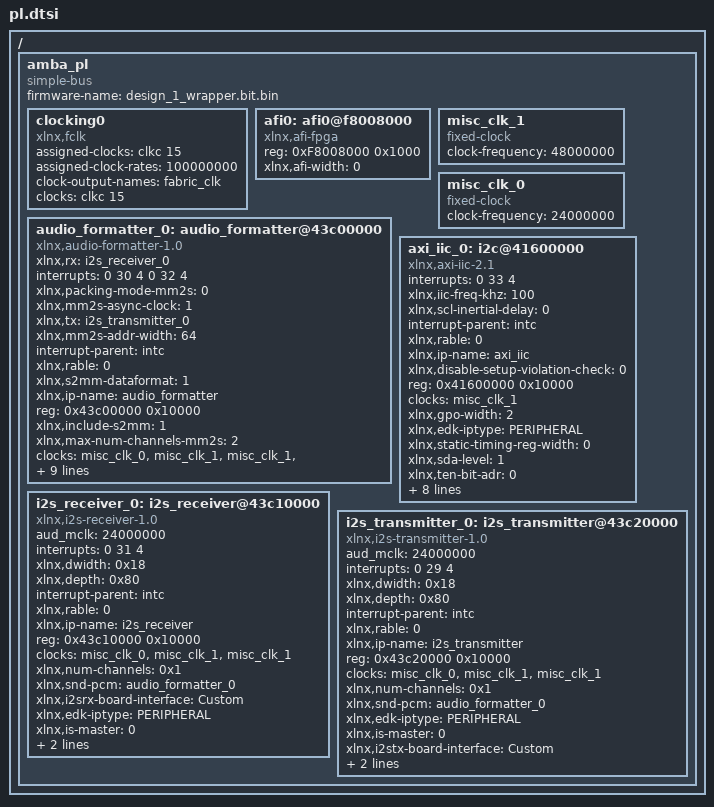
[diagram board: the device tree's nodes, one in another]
/ {
	amba_pl: amba_pl {
		ranges;
		compatible = "simple-bus";
		#address-cells = <1>;
		#size-cells = <1>;
		firmware-name = "design_1_wrapper.bit.bin";
		clocking0: clocking0 {
			compatible = "xlnx,fclk";
			assigned-clocks = <&clkc 15>;
			assigned-clock-rates = <100000000>;
			#clock-cells = <0>;
			clock-output-names = "fabric_clk";
			clocks = <&clkc 15>;
		};
		afi0: afi0@f8008000 {
			status = "okay";
			compatible = "xlnx,afi-fpga";
			#address-cells = <1>;
			reg = <0xF8008000 0x1000>;
			#size-cells = <0>;
			xlnx,afi-width = <0>;
		};
		misc_clk_1: misc_clk_1 {
			compatible = "fixed-clock";
			clock-frequency = <48000000>;
			#clock-cells = <0>;
		};
		misc_clk_0: misc_clk_0 {
			compatible = "fixed-clock";
			clock-frequency = <24000000>;
			#clock-cells = <0>;
		};
		audio_formatter_0: audio_formatter@43c00000 {
			xlnx,rx = <&i2s_receiver_0>;
			interrupts = < 0 30 4 0 32 4 >;
			compatible = "xlnx,audio-formatter-1.0" , "xlnx,audio-formatter-1.0";
			xlnx,packing-mode-mm2s = <0>;
			xlnx,mm2s-async-clock = <1>;
			xlnx,tx = <&i2s_transmitter_0>;
			xlnx,mm2s-addr-width = <64>;
			interrupt-parent = <&intc>;
			xlnx,rable = <0>;
			xlnx,s2mm-dataformat = <1>;
			xlnx,ip-name = "audio_formatter";
			reg = <0x43c00000 0x10000>;
			xlnx,include-s2mm = <1>;
			xlnx,max-num-channels-mm2s = <2>;
			clocks = <&misc_clk_0>, <&misc_clk_1>, <&misc_clk_1>, <&misc_clk_1>;
			xlnx,s2mm-async-clock = <1>;
			xlnx,packing-mode-s2mm = <0>;
			xlnx,edk-iptype = "PERIPHERAL";
			xlnx,s2mm-addr-width = <64>;
			status = "okay";
			clock-names = "aud_mclk" , "m_axis_mm2s_aclk" , "s_axi_lite_aclk" , "s_axis_s2mm_aclk";
			xlnx,mm2s-dataformat = <3>;
			interrupt-names = "irq_mm2s" , "irq_s2mm";
			xlnx,include-mm2s = <1>;
			xlnx,max-num-channels-s2mm = <2>;
			xlnx,name = "audio_formatter_0";
		};
		axi_iic_0: i2c@41600000 {
			interrupts = < 0 33 4 >;
			xlnx,iic-freq-khz = <100>;
			compatible = "xlnx,axi-iic-2.1" , "xlnx,xps-iic-2.00.a";
			xlnx,scl-inertial-delay = <0>;
			interrupt-parent = <&intc>;
			xlnx,rable = <0>;
			xlnx,ip-name = "axi_iic";
			xlnx,disable-setup-violation-check = <0>;
			reg = <0x41600000 0x10000>;
			clocks = <&misc_clk_1>;
			xlnx,gpo-width = <2>;
			xlnx,edk-iptype = "PERIPHERAL";
			xlnx,static-timing-reg-width = <0>;
			xlnx,sda-level = <1>;
			status = "okay";
			clock-names = "s_axi_aclk";
			xlnx,ten-bit-adr = <0>;
			xlnx,default-value = <0x0>;
			interrupt-names = "iic2intc_irpt";
			xlnx,iic-board-interface = "Custom";
			xlnx,timing-reg-width = <32>;
			xlnx,iic-freq = <100000>;
			xlnx,smbus-pmbus-host = <0>;
			xlnx,name = "axi_iic_0";
			xlnx,axi-aclk-freq-mhz = <48>;
			xlnx,sda-inertial-delay = <0>;
		};
		i2s_receiver_0: i2s_receiver@43c10000 {
			aud_mclk = <24000000>;
			interrupts = < 0 31 4 >;
			compatible = "xlnx,i2s-receiver-1.0" , "xlnx,i2s-receiver-1.0";
			xlnx,dwidth = <0x18>;
			xlnx,depth = <0x80>;
			interrupt-parent = <&intc>;
			xlnx,rable = <0>;
			xlnx,ip-name = "i2s_receiver";
			reg = <0x43c10000 0x10000>;
			clocks = <&misc_clk_0>, <&misc_clk_1>, <&misc_clk_1>;
			xlnx,num-channels = <0x1>;
			xlnx,snd-pcm = <&audio_formatter_0>;
			xlnx,i2srx-board-interface = "Custom";
			xlnx,edk-iptype = "PERIPHERAL";
			xlnx,is-master = <0>;
			status = "okay";
			clock-names = "aud_mclk" , "m_axis_aud_aclk" , "s_axi_ctrl_aclk";
			xlnx,32bit-lr = <0>;
			interrupt-names = "irq";
			xlnx,name = "i2s_receiver_0";
		};
		i2s_transmitter_0: i2s_transmitter@43c20000 {
			aud_mclk = <24000000>;
			interrupts = < 0 29 4 >;
			compatible = "xlnx,i2s-transmitter-1.0" , "xlnx,i2s-transmitter-1.0";
			xlnx,dwidth = <0x18>;
			xlnx,depth = <0x80>;
			interrupt-parent = <&intc>;
			xlnx,rable = <0>;
			xlnx,ip-name = "i2s_transmitter";
			reg = <0x43c20000 0x10000>;
			clocks = <&misc_clk_0>, <&misc_clk_1>, <&misc_clk_1>;
			xlnx,num-channels = <0x1>;
			xlnx,snd-pcm = <&audio_formatter_0>;
			xlnx,edk-iptype = "PERIPHERAL";
			xlnx,is-master = <0>;
			xlnx,i2stx-board-interface = "Custom";
			status = "okay";
			clock-names = "aud_mclk" , "s_axi_ctrl_aclk" , "s_axis_aud_aclk";
			xlnx,32bit-lr = <0>;
			interrupt-names = "irq";
			xlnx,name = "i2s_transmitter_0";
		};
	};
};
